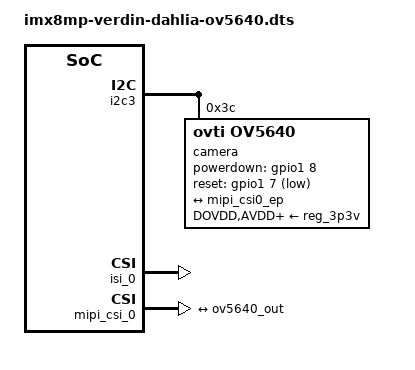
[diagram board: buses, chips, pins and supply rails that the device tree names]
// SPDX-License-Identifier: GPL-2.0+ OR MIT
/*
 * Copyright 2022 Ideas on Board Oy
 */

/dts-v1/;
/plugin/;

#include <dt-bindings/gpio/gpio.h>

/ {
	fragment@0 {
		target = <&i2c3>;
		__overlay__ {
			status = "okay";

			camera@3c {
				compatible = "ovti,ov5640";
				reg = <0x3c>;

				pinctrl-names = "default";
				pinctrl-0 = <&pinctrl_gpio5>, <&pinctrl_gpio6>;

				clocks = <&ov5640_clk>;
				clock-names = "xclk";
/*
				assigned-clocks = <&clk IMX8MP_CLK_IPP_DO_CLKO2>;
				assigned-clock-parents = <&clk IMX8MP_CLK_24M>;
				assigned-clock-rates = <24000000>;
*/

				DOVDD-supply = <&reg_3p3v>;
				AVDD-supply = <&reg_3p3v>;
				DVDD-supply = <&reg_3p3v>;

				powerdown-gpios = <&gpio1 8 GPIO_ACTIVE_HIGH>;
				reset-gpios = <&gpio1 7 GPIO_ACTIVE_LOW>;

				port {
					ov5640_out: endpoint {
						remote-endpoint = <&mipi_csi0_ep>;
						clock-lanes = <0>;
						data-lanes = <1 2>;
					};
				};
			};
		};
	};

	fragment@1 {
		target = <&isi_0>;
		__overlay__ {
			status = "okay";
		};
	};

	fragment@2 {
		target = <&mipi_csi_0>;
		__overlay__ {
			status = "okay";

			ports {
				port@0 {
					mipi_csi0_ep: endpoint {
						remote-endpoint = <&ov5640_out>;
						data-lanes = <1 2>;
					};
				};
			};
		};
	};

	fragment@3 {
		target-path = "/";
		__overlay__ {
			ov5640_clk: ov5640-clk {
				compatible = "fixed-clock";
				#clock-cells = <0>;
				clock-frequency = <24000000>;
			};
		};
	};
};
